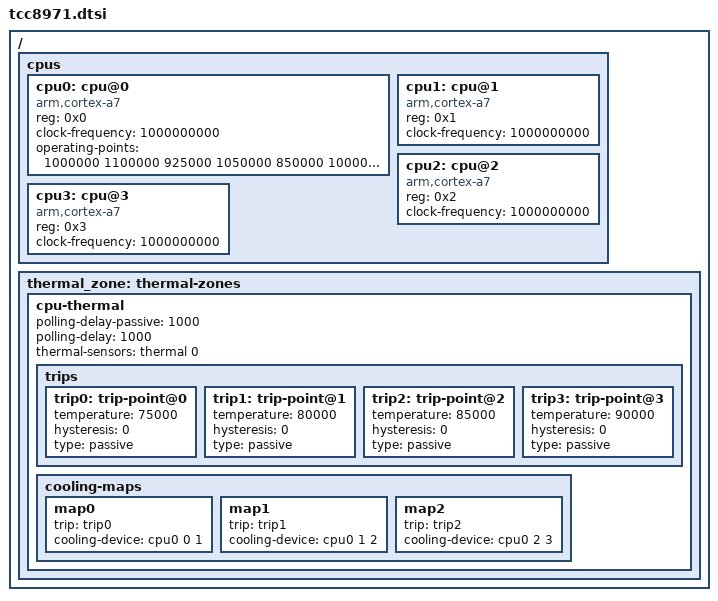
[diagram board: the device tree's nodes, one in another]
// SPDX-License-Identifier: (GPL-2.0-or-later OR MIT)
/*
 * Copyright (C) Telechips Inc.
 */

#include "tcc897x.dtsi"
#include "tcc897x-pinctrl.dtsi"

/ {
	cpus {
		#address-cells = <1>;
		#size-cells = <0>;

		cpu0: cpu@0 {
			device_type = "cpu";
			compatible = "arm,cortex-a7";
			reg = <0x0>;
			clock-frequency = <1000000000>;
			#cooling-cells = <2>;
			operating-points = <
				/* kHz    uV */
				1000000	1100000
				 925000	1050000
				 850000	1000000
				 775000	 950000
				 700000	 900000
			>;
		};
		cpu1: cpu@1 {
			device_type = "cpu";
			compatible = "arm,cortex-a7";
			reg = <0x1>;
			clock-frequency = <1000000000>;
			#cooling-cells = <2>;
		};
		cpu2: cpu@2 {
			device_type = "cpu";
			compatible = "arm,cortex-a7";
			reg = <0x2>;
			clock-frequency = <1000000000>;
			#cooling-cells = <2>;
		};
		cpu3: cpu@3 {
			device_type = "cpu";
			compatible = "arm,cortex-a7";
			reg = <0x3>;
			clock-frequency = <1000000000>;
			#cooling-cells = <2>;
		};
	};
	thermal_zone: thermal-zones {
		cpu-thermal {
			polling-delay-passive = <1000>;
			polling-delay = <1000>;
			thermal-sensors = <&thermal 0>;
			trips {
				trip0: trip-point@0 {
					temperature = <75000>;
					hysteresis = <0>;
					type = "passive";
				};
				trip1: trip-point@1 {
					temperature = <80000>;
					hysteresis = <0>;
					type = "passive";
				};
				trip2: trip-point@2 {
					temperature = <85000>;
					hysteresis = <0>;
					type = "passive";
				};
				trip3: trip-point@3 {
					temperature = <90000>;
					hysteresis = <0>;
					type = "passive";
				};
			};
			cooling-maps {
				map0 {
					trip = <&trip0>;
					cooling-device =
						<&cpu0 0 1>;
				};
				map1 {
					trip = <&trip1>;
					cooling-device =
					<&cpu0 1 2>;
				};
				map2 {
					trip = <&trip2>;
					cooling-device =
					<&cpu0 2 3>;
				};
			};
		};
	};
};
